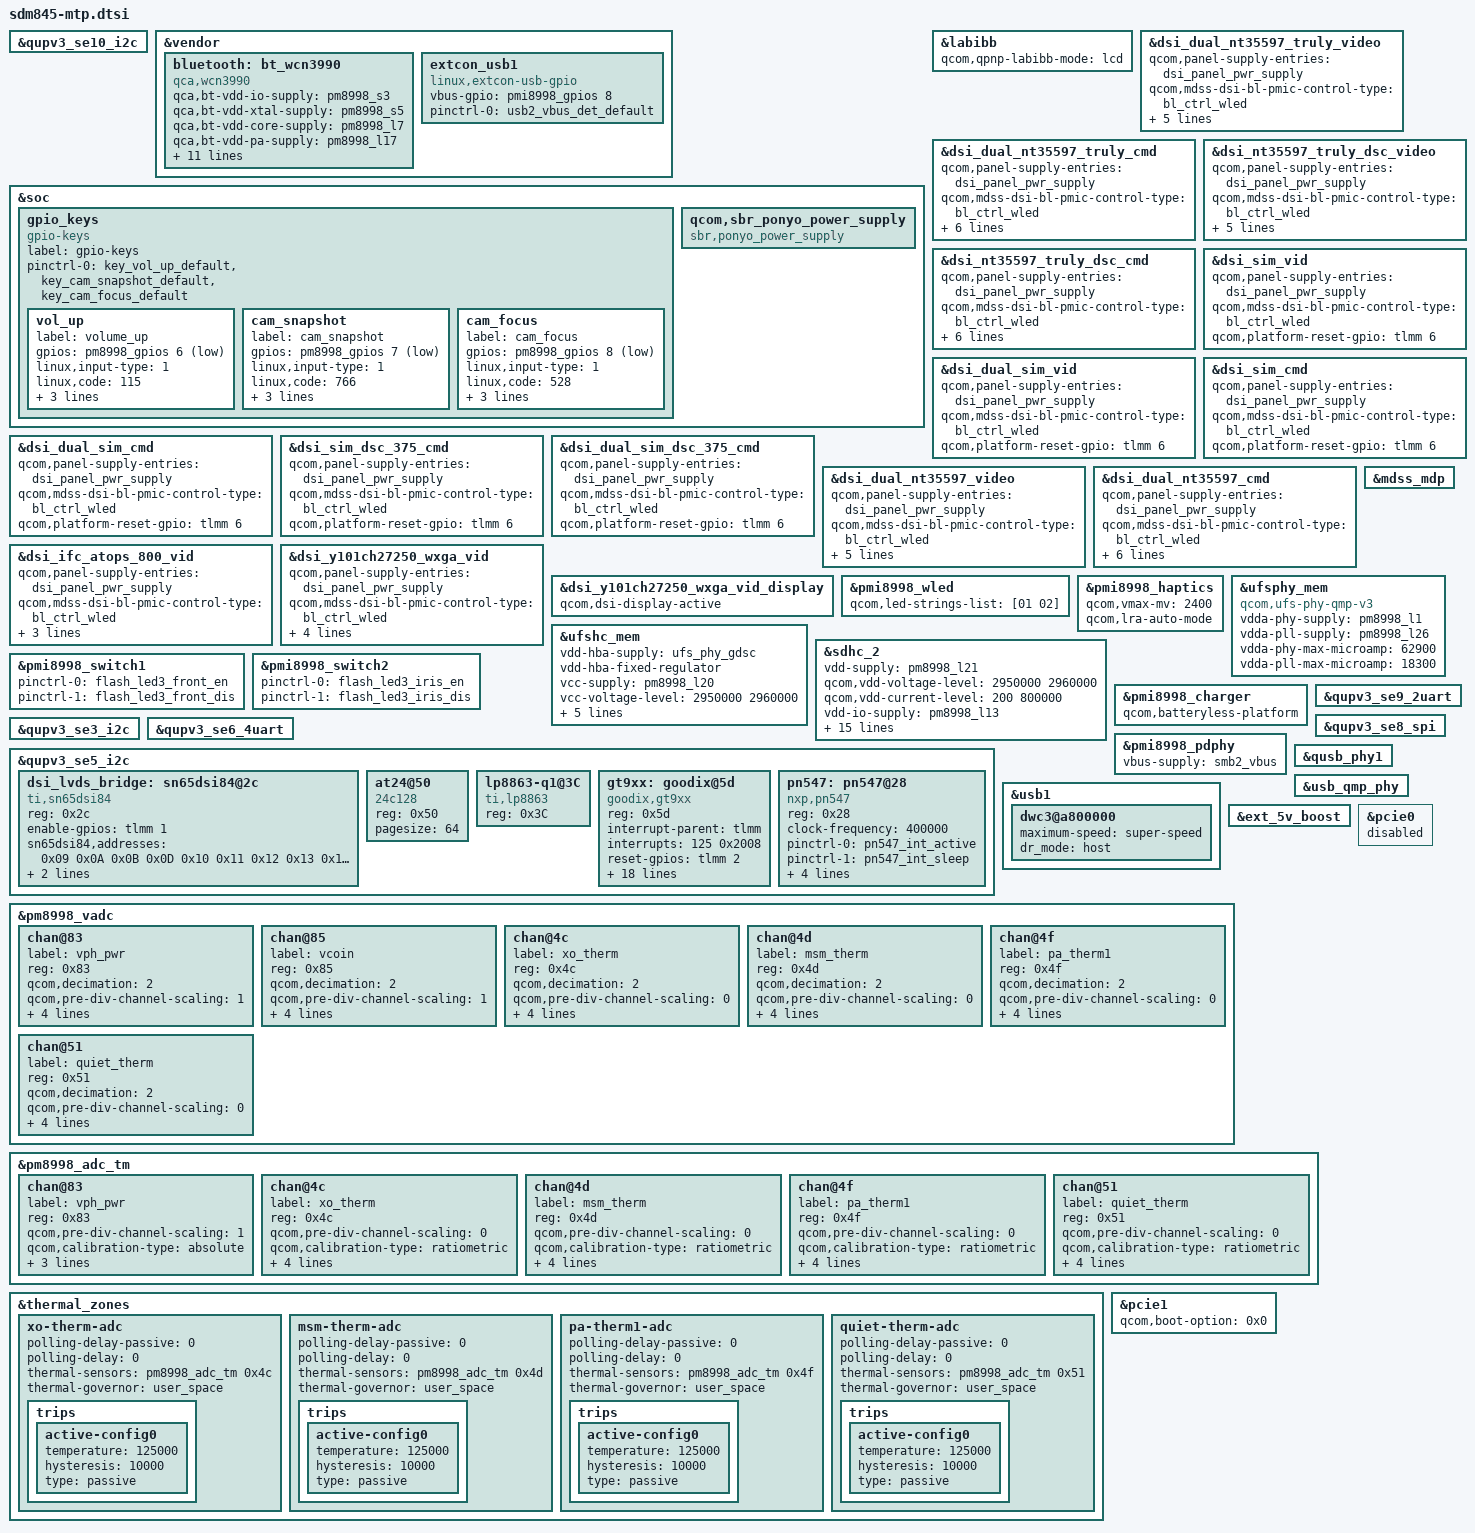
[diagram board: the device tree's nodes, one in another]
/* Copyright (c) 2016-2018, The Linux Foundation. All rights reserved.
 *
 * This program is free software; you can redistribute it and/or modify
 * it under the terms of the GNU General Public License version 2 and
 * only version 2 as published by the Free Software Foundation.
 *
 * This program is distributed in the hope that it will be useful,
 * but WITHOUT ANY WARRANTY; without even the implied warranty of
 * MERCHANTABILITY or FITNESS FOR A PARTICULAR PURPOSE.  See the
 * GNU General Public License for more details.
 */

#include <dt-bindings/gpio/gpio.h>
#include "sdm845-pmic-overlay.dtsi"
#include "sdm845-pinctrl-overlay.dtsi"
#include "sdm845-camera-sensor-mtp.dtsi"

&qupv3_se10_i2c {
#include "smb1355.dtsi"
};

&vendor {
	bluetooth: bt_wcn3990 {
		compatible = "qca,wcn3990";
		qca,bt-vdd-io-supply = <&pm8998_s3>;
		qca,bt-vdd-xtal-supply = <&pm8998_s5>;
		qca,bt-vdd-core-supply = <&pm8998_l7>;
		qca,bt-vdd-pa-supply = <&pm8998_l17>;
		qca,bt-vdd-ldo-supply = <&pm8998_l25>;

		qca,bt-vdd-io-voltage-level = <1352000 1352000>;
		qca,bt-vdd-xtal-voltage-level = <2040000 2040000>;
		qca,bt-vdd-core-voltage-level = <1800000 1800000>;
		qca,bt-vdd-pa-voltage-level = <1304000 1304000>;
		qca,bt-vdd-ldo-voltage-level = <3312000 3312000>;

		qca,bt-vdd-io-current-level = <1>; /* LPM/PFM */
		qca,bt-vdd-xtal-current-level = <1>; /* LPM/PFM */
		qca,bt-vdd-core-current-level = <1>; /* LPM/PFM */
		qca,bt-vdd-pa-current-level = <1>; /* LPM/PFM */
		qca,bt-vdd-ldo-current-level = <1>; /* LPM/PFM */
	};
};

&soc {
	gpio_keys {
		compatible = "gpio-keys";
		label = "gpio-keys";

		pinctrl-names = "default";
		pinctrl-0 = <&key_vol_up_default
			     &key_cam_snapshot_default
			     &key_cam_focus_default>;

		vol_up {
			label = "volume_up";
			gpios = <&pm8998_gpios 6 GPIO_ACTIVE_LOW>;
			linux,input-type = <1>;
			linux,code = <115>;
			gpio-key,wakeup;
			debounce-interval = <15>;
			linux,can-disable;
		};

		cam_snapshot {
			label = "cam_snapshot";
			gpios = <&pm8998_gpios 7 GPIO_ACTIVE_LOW>;
			linux,input-type = <1>;
			linux,code = <766>;
			gpio-key,wakeup;
			debounce-interval = <15>;
			linux,can-disable;
		};

		cam_focus {
			label = "cam_focus";
			gpios = <&pm8998_gpios 8 GPIO_ACTIVE_LOW>;
			linux,input-type = <1>;
			linux,code = <528>;
			gpio-key,wakeup;
			debounce-interval = <15>;
			linux,can-disable;
		};
	};

	qcom,sbr_ponyo_power_supply {
		compatible = "sbr,ponyo_power_supply";
		status = "okay";
	};

};

&labibb {
	status = "ok";
	qcom,qpnp-labibb-mode = "lcd";
};

&dsi_dual_nt35597_truly_video {
	qcom,panel-supply-entries = <&dsi_panel_pwr_supply>;
	qcom,mdss-dsi-bl-pmic-control-type = "bl_ctrl_wled";
	qcom,mdss-dsi-bl-min-level = <1>;
	qcom,mdss-dsi-bl-max-level = <4095>;
	qcom,mdss-dsi-mode-sel-gpio-state = "dual_port";
	qcom,panel-mode-gpio = <&tlmm 52 0>;
	qcom,platform-reset-gpio = <&tlmm 6 0>;
};

&dsi_dual_nt35597_truly_cmd {
	qcom,panel-supply-entries = <&dsi_panel_pwr_supply>;
	qcom,mdss-dsi-bl-pmic-control-type = "bl_ctrl_wled";
	qcom,mdss-dsi-bl-min-level = <1>;
	qcom,mdss-dsi-bl-max-level = <4095>;
	qcom,mdss-dsi-mode-sel-gpio-state = "dual_port";
	qcom,panel-mode-gpio = <&tlmm 52 0>;
	qcom,platform-reset-gpio = <&tlmm 6 0>;
	qcom,platform-te-gpio = <&tlmm 10 0>;
};

&dsi_nt35597_truly_dsc_video {
	qcom,panel-supply-entries = <&dsi_panel_pwr_supply>;
	qcom,mdss-dsi-bl-pmic-control-type = "bl_ctrl_wled";
	qcom,mdss-dsi-bl-min-level = <1>;
	qcom,mdss-dsi-bl-max-level = <4095>;
	qcom,mdss-dsi-mode-sel-gpio-state = "single_port";
	qcom,panel-mode-gpio = <&tlmm 52 0>;
	qcom,platform-reset-gpio = <&tlmm 6 0>;
};

&dsi_nt35597_truly_dsc_cmd {
	qcom,panel-supply-entries = <&dsi_panel_pwr_supply>;
	qcom,mdss-dsi-bl-pmic-control-type = "bl_ctrl_wled";
	qcom,mdss-dsi-bl-min-level = <1>;
	qcom,mdss-dsi-bl-max-level = <4095>;
	qcom,mdss-dsi-mode-sel-gpio-state = "single_port";
	qcom,panel-mode-gpio = <&tlmm 52 0>;
	qcom,platform-reset-gpio = <&tlmm 6 0>;
	qcom,platform-te-gpio = <&tlmm 10 0>;
};

&dsi_sim_vid {
	qcom,panel-supply-entries = <&dsi_panel_pwr_supply>;
	qcom,mdss-dsi-bl-pmic-control-type = "bl_ctrl_wled";
	qcom,platform-reset-gpio = <&tlmm 6 0>;
};

&dsi_dual_sim_vid {
	qcom,panel-supply-entries = <&dsi_panel_pwr_supply>;
	qcom,mdss-dsi-bl-pmic-control-type = "bl_ctrl_wled";
	qcom,platform-reset-gpio = <&tlmm 6 0>;
};

&dsi_sim_cmd {
	qcom,panel-supply-entries = <&dsi_panel_pwr_supply>;
	qcom,mdss-dsi-bl-pmic-control-type = "bl_ctrl_wled";
	qcom,platform-reset-gpio = <&tlmm 6 0>;
};

&dsi_dual_sim_cmd {
	qcom,panel-supply-entries = <&dsi_panel_pwr_supply>;
	qcom,mdss-dsi-bl-pmic-control-type = "bl_ctrl_wled";
	qcom,platform-reset-gpio = <&tlmm 6 0>;
};

&dsi_sim_dsc_375_cmd {
	qcom,panel-supply-entries = <&dsi_panel_pwr_supply>;
	qcom,mdss-dsi-bl-pmic-control-type = "bl_ctrl_wled";
	qcom,platform-reset-gpio = <&tlmm 6 0>;
};

&dsi_dual_sim_dsc_375_cmd {
	qcom,panel-supply-entries = <&dsi_panel_pwr_supply>;
	qcom,mdss-dsi-bl-pmic-control-type = "bl_ctrl_wled";
	qcom,platform-reset-gpio = <&tlmm 6 0>;
};

&dsi_dual_nt35597_video {
	qcom,panel-supply-entries = <&dsi_panel_pwr_supply>;
	qcom,mdss-dsi-bl-pmic-control-type = "bl_ctrl_wled";
	qcom,mdss-dsi-bl-min-level = <1>;
	qcom,mdss-dsi-bl-max-level = <4095>;
	qcom,mdss-dsi-mode-sel-gpio-state = "dual_port";
	qcom,panel-mode-gpio = <&tlmm 52 0>;
	qcom,platform-reset-gpio = <&tlmm 6 0>;

};

&dsi_dual_nt35597_cmd {
	qcom,panel-supply-entries = <&dsi_panel_pwr_supply>;
	qcom,mdss-dsi-bl-pmic-control-type = "bl_ctrl_wled";
	qcom,mdss-dsi-bl-min-level = <1>;
	qcom,mdss-dsi-bl-max-level = <4095>;
	qcom,mdss-dsi-mode-sel-gpio-state = "dual_port";
	qcom,panel-mode-gpio = <&tlmm 52 0>;
	qcom,platform-reset-gpio = <&tlmm 6 0>;
	qcom,platform-te-gpio = <&tlmm 10 0>;
};

&dsi_ifc_atops_800_vid {
	qcom,panel-supply-entries = <&dsi_panel_pwr_supply>;
        qcom,mdss-dsi-bl-pmic-control-type = "bl_ctrl_wled";
        qcom,mdss-dsi-bl-min-level = <1>;
        qcom,mdss-dsi-bl-max-level = <4095>;
	qcom,platform-reset-gpio = <&tlmm 87 0>;
	//qcom,mdss-dsi-mode-sel-gpio-state = "single_port";
	//qcom,platform-bklight-en-gpio = <&tlmm 88 0>;
	//qcom,mdss-dsi-pwm-gpio = <&pmi8998_gpios 5 GPIO_ACTIVE_HIGH>;
};

&dsi_y101ch27250_wxga_vid {
	qcom,panel-supply-entries = <&dsi_panel_pwr_supply>;
	qcom,mdss-dsi-bl-pmic-control-type = "bl_ctrl_wled";
	qcom,mdss-dsi-bl-min-level = <1>;
	qcom,mdss-dsi-bl-max-level = <4095>;
	qcom,platform-reset-gpio = <&tlmm 87 0>;
	qcom,mdss-dsi-mode-sel-gpio-state = "single_port";
};

/*
&dsi_nt35597_truly_dsc_cmd_display {
	qcom,dsi-display-active;
}; */
/*
&dsi_ifc_atops_800_vid_display {
	qcom,dsi-display-active;
};
*/
&dsi_y101ch27250_wxga_vid_display {
	qcom,dsi-display-active;
};
/*
&dsi_sim_vid_display {
	qcom,dsi-display-active;
};*/

&pmi8998_wled {
	status = "okay";
	qcom,led-strings-list = [01 02];
};

&pmi8998_haptics {
	qcom,vmax-mv = <2400>;
	qcom,lra-auto-mode;
	status = "okay";
};

&mdss_mdp {
	#cooling-cells = <2>;
};

&ufsphy_mem {
	compatible = "qcom,ufs-phy-qmp-v3";

	vdda-phy-supply = <&pm8998_l1>; /* 0.88v */
	vdda-pll-supply = <&pm8998_l26>; /* 1.2v */
	vdda-phy-max-microamp = <62900>;
	vdda-pll-max-microamp = <18300>;

	status = "ok";
};

&ufshc_mem {
	vdd-hba-supply = <&ufs_phy_gdsc>;
	vdd-hba-fixed-regulator;
	vcc-supply = <&pm8998_l20>;
	vcc-voltage-level = <2950000 2960000>;
	vccq2-supply = <&pm8998_s4>;
	vcc-max-microamp = <600000>;
	vccq2-max-microamp = <600000>;

	qcom,vddp-ref-clk-supply = <&pm8998_l2>;
	qcom,vddp-ref-clk-max-microamp = <100>;

	status = "ok";
};

&sdhc_2 {
	vdd-supply = <&pm8998_l21>;
	qcom,vdd-voltage-level = <2950000 2960000>;
	qcom,vdd-current-level = <200 800000>;

	vdd-io-supply = <&pm8998_l13>;
	qcom,vdd-io-voltage-level = <1808000 2960000>;
	qcom,vdd-io-current-level = <200 22000>;

	pinctrl-names = "active", "sleep", "ds_400KHz",
			"ds_50MHz", "ds_100MHz", "ds_200MHz";
	pinctrl-0 = <&sdc2_clk_on  &sdc2_cmd_on &sdc2_data_on &storage_cd>;
	pinctrl-1 = <&sdc2_clk_off &sdc2_cmd_off &sdc2_data_off &storage_cd>;
	pinctrl-2 = <&sdc2_clk_ds_400KHz
			&sdc2_cmd_ds_400KHz &sdc2_data_ds_400KHz>;
	pinctrl-3 = <&sdc2_clk_ds_50MHz
			&sdc2_cmd_ds_50MHz &sdc2_data_ds_50MHz>;
	pinctrl-4 = <&sdc2_clk_ds_100MHz
			&sdc2_cmd_ds_100MHz &sdc2_data_ds_100MHz>;
	pinctrl-5 = <&sdc2_clk_ds_200MHz
			&sdc2_cmd_ds_200MHz &sdc2_data_ds_200MHz>;

	cd-gpios = <&tlmm 126 GPIO_ACTIVE_LOW>;

	status = "ok";
};

&pmi8998_switch1 {
	pinctrl-names = "led_enable", "led_disable";
	pinctrl-0 = <&flash_led3_front_en>;
	pinctrl-1 = <&flash_led3_front_dis>;
};

&pmi8998_switch2 {
	pinctrl-names = "led_enable", "led_disable";
	pinctrl-0 = <&flash_led3_iris_en>;
	pinctrl-1 = <&flash_led3_iris_dis>;
};

&pmi8998_charger {
        qcom,batteryless-platform;
};


&vendor {

	extcon_usb1: extcon_usb1 {
		compatible = "linux,extcon-usb-gpio";
		vbus-gpio = <&pmi8998_gpios 8 GPIO_ACTIVE_HIGH>;

		pinctrl-names = "default";
		pinctrl-0 = <&usb2_vbus_det_default>;
	};
};

&qupv3_se9_2uart {
	status = "ok";
};

&qupv3_se8_spi {
	status = "ok";
};

&qupv3_se3_i2c {
	status = "ok";
/*
	nq@28 {
		compatible = "qcom,nq-nci";
		reg = <0x28>;
		qcom,nq-irq = <&tlmm 63 0x00>;
		qcom,nq-ven = <&tlmm 12 0x00>;
		qcom,nq-firm = <&tlmm 62 0x00>;
		qcom,nq-clkreq = <&pm8998_gpios 21 0x00>;
		qcom,nq-esepwr = <&tlmm 116 0x00>;
		interrupt-parent = <&tlmm>;
		interrupts = <63 0>;
		interrupt-names = "nfc_irq";
		pinctrl-names = "nfc_active", "nfc_suspend";
		pinctrl-0 = <&nfc_int_active
			     &nfc_enable_active
			     &nfc_clk_default>;
		pinctrl-1 = <&nfc_int_suspend &nfc_enable_suspend>;
	};
*/
};

&qupv3_se10_i2c {
	status = "ok";
};

&qupv3_se6_4uart {
	status = "ok";
};

&qupv3_se5_i2c {
	status = "ok";

	dsi_lvds_bridge: sn65dsi84@2c {
		compatible = "ti,sn65dsi84";
		reg = <0x2c>;
		status = "okay";

		enable-gpios = <&tlmm 1 0x00>;

		sn65dsi84,addresses = < 0x09 0x0A 0x0B 0x0D 0x10 0x11 0x12 0x13
			                0x18 0x19 0x1A 0x1B 0x20 0x21 0x22 0x23
			                0x24 0x25 0x26 0x27 0x28 0x29 0x2A 0x2B
			                0x2C 0x2D 0x2E 0x2F 0x30 0x31 0x32 0x33
			                0x34 0x35 0x36 0x37 0x38 0x39 0x3A 0x3B
			                0x3C 0x3D 0x3E 0x0D>;

		sn65dsi84,values =    < 0x00 0x05 0x10 0x00 0x26 0x00 0x2B 0x00
			                0x58 0x05 0x03 0x00 0x20 0x03 0x00 0x00
			                0x00 0x00 0x00 0x00 0x21 0x00 0x00 0x00
			                0x18 0x00 0x00 0x00 0x03 0x00 0x00 0x00
			                0x38 0x00 0x14 0x00 0x50 0x00 0x00 0x00
			                0x00 0x00 0x00 0x01>;
	};

	at24@50 {
		compatible = "24c128";
		reg = <0x50>;
		pagesize = <64>;
		status = "ok";
	};

	lp8863-q1@3C {
		status = "okay";
		compatible = "ti,lp8863";
		reg = <0x3C>;
	};

	gt9xx: goodix@5d {
		status = "okay";
		compatible = "goodix,gt9xx";
		reg = <0x5d>;
		interrupt-parent = <&tlmm>;
		interrupts = <125 0x2008>;
		reset-gpios = <&tlmm 2 0x00>;
		irq-gpios = <&tlmm 125 0x2008>;
		pinctrl-names = "gdix_ts_int_default", "gdix_ts_int_output_low",
			"gdix_ts_int_output_high", "gdix_ts_int_input",
			"gdix_ts_rst_default", "gdix_ts_rst_output_low",
			"gdix_ts_rst_output_high", "gdix_ts_rst_input";
		pinctrl-0 = <&ts_int_active>;
		pinctrl-1 = <&ts_int_suspend>;
		pinctrl-2 = <&ts_int_active>;
		pinctrl-3 = <&ts_int_active>;
		pinctrl-4 = <&ts_reset_active>;
		pinctrl-5 = <&ts_reset_suspend>;
		pinctrl-6 = <&ts_reset_active>;
		pinctrl-7 = <&ts_reset_active>;
		goodix,swap-x2y = <1>;
		touchscreen-size-x= <1280>;
		touchscreen-size-y= <800>;
		touchscreen-max-w = <255>;
		touchscreen-max-p = <255>;
		touchscreen-max-id= <255>;
		touchscreen-key-map= <158>, <102>, <139>;
		goodix,cfg-group0 = [
		00 20 03 00 05 0A 0C 00 01 0F
		14 0F 5A 46 03 05 00 00 00 00
		00 00 00 0D 0F 12 0A 8F 2F AA
		38 3B D3 07 00 00 00 9A 03 25
		00 00 00 00 00 00 00 00 00 00
		00 23 50 94 C5 02 07 00 00 04
		A9 26 00 95 2D 00 85 35 00 77
		3E 00 6C 49 00 6C 00 00 00 00
		00 00 00 00 00 00 00 00 00 00
		00 00 00 00 00 00 00 00 00 00
		00 00 00 00 00 00 00 00 00 00
		00 00 00 01 04 05 06 07 08 09
		0C 0D 0E 0F 10 11 14 15 16 17
		18 19 00 00 00 00 00 00 00 00
		00 00 00 02 04 06 07 08 0A 0C
		0D 0F 10 11 12 13 14 19 1B 1C
		1E 1F 20 21 22 23 24 25 26 27
		28 29 FF FF 00 00 00 00 00 00
		00 00 00 00 99 01];

	};

	pn547: pn547@28 {
	       status = "okay";
	       compatible = "nxp,pn547";
	       reg = <0x28>;
	       clock-frequency = <400000>;
	       pinctrl-names = "pn547_int_active", "pn547_int_sleep", "pn547_reset_active", "pn547_reset_sleep";
	       pinctrl-0 = <&pn547_int_active>;
	       pinctrl-1 = <&pn547_int_sleep>;
	       pinctrl-2 = <&pn547_reset_active>;
	       pinctrl-3 = <&pn547_reset_sleep>;
	       interrupt-gpios = <&tlmm 83 0x2008>;
	       enable-gpios = <&tlmm 84 0x00>;
       };
};

/*
&usb1 {
	extcon = <&extcon_usb1>;
};
*/

&pmi8998_pdphy {
	vbus-supply = <&smb2_vbus>;
};

&usb1 {
	status = "ok";
	dwc3@a800000 {
		maximum-speed = "super-speed";
		dr_mode = "host";
	};
};

&qusb_phy1 {
	status = "ok";
};

&usb_qmp_phy {
	status = "ok";
};


&ext_5v_boost {
	status = "ok";
};

&pm8998_vadc {
	chan@83 {
		label = "vph_pwr";
		reg = <0x83>;
		qcom,decimation = <2>;
		qcom,pre-div-channel-scaling = <1>;
		qcom,calibration-type = "absolute";
		qcom,scale-function = <0>;
		qcom,hw-settle-time = <0>;
		qcom,fast-avg-setup = <0>;
	};

	chan@85 {
		label = "vcoin";
		reg = <0x85>;
		qcom,decimation = <2>;
		qcom,pre-div-channel-scaling = <1>;
		qcom,calibration-type = "absolute";
		qcom,scale-function = <0>;
		qcom,hw-settle-time = <0>;
		qcom,fast-avg-setup = <0>;
	};

	chan@4c {
		label = "xo_therm";
		reg = <0x4c>;
		qcom,decimation = <2>;
		qcom,pre-div-channel-scaling = <0>;
		qcom,calibration-type = "ratiometric";
		qcom,scale-function = <4>;
		qcom,hw-settle-time = <2>;
		qcom,fast-avg-setup = <0>;
	};

	chan@4d {
		label = "msm_therm";
		reg = <0x4d>;
		qcom,decimation = <2>;
		qcom,pre-div-channel-scaling = <0>;
		qcom,calibration-type = "ratiometric";
		qcom,scale-function = <2>;
		qcom,hw-settle-time = <2>;
		qcom,fast-avg-setup = <0>;
	};

	chan@4f {
		label = "pa_therm1";
		reg = <0x4f>;
		qcom,decimation = <2>;
		qcom,pre-div-channel-scaling = <0>;
		qcom,calibration-type = "ratiometric";
		qcom,scale-function = <2>;
		qcom,hw-settle-time = <2>;
		qcom,fast-avg-setup = <0>;
	};

	chan@51 {
		label = "quiet_therm";
		reg = <0x51>;
		qcom,decimation = <2>;
		qcom,pre-div-channel-scaling = <0>;
		qcom,calibration-type = "ratiometric";
		qcom,scale-function = <2>;
		qcom,hw-settle-time = <2>;
		qcom,fast-avg-setup = <0>;
	};
};

&pm8998_adc_tm {
	chan@83 {
		label = "vph_pwr";
		reg = <0x83>;
		qcom,pre-div-channel-scaling = <1>;
		qcom,calibration-type = "absolute";
		qcom,scale-function = <0>;
		qcom,hw-settle-time = <0>;
		qcom,btm-channel-number = <0x60>;
	};

	chan@4c {
		label = "xo_therm";
		reg = <0x4c>;
		qcom,pre-div-channel-scaling = <0>;
		qcom,calibration-type = "ratiometric";
		qcom,scale-function = <4>;
		qcom,hw-settle-time = <2>;
		qcom,btm-channel-number = <0x68>;
		qcom,thermal-node;
	};

	chan@4d {
		label = "msm_therm";
		reg = <0x4d>;
		qcom,pre-div-channel-scaling = <0>;
		qcom,calibration-type = "ratiometric";
		qcom,scale-function = <2>;
		qcom,hw-settle-time = <2>;
		qcom,btm-channel-number = <0x70>;
		qcom,thermal-node;
	};

	chan@4f {
		label = "pa_therm1";
		reg = <0x4f>;
		qcom,pre-div-channel-scaling = <0>;
		qcom,calibration-type = "ratiometric";
		qcom,scale-function = <2>;
		qcom,hw-settle-time = <2>;
		qcom,btm-channel-number = <0x78>;
		qcom,thermal-node;
	};

	chan@51 {
		label = "quiet_therm";
		reg = <0x51>;
		qcom,pre-div-channel-scaling = <0>;
		qcom,calibration-type = "ratiometric";
		qcom,scale-function = <2>;
		qcom,hw-settle-time = <2>;
		qcom,btm-channel-number = <0x80>;
		qcom,thermal-node;
	};
};

&thermal_zones {
	xo-therm-adc {
		polling-delay-passive = <0>;
		polling-delay = <0>;
		thermal-sensors = <&pm8998_adc_tm 0x4c>;
		thermal-governor = "user_space";

		trips {
			active-config0 {
				temperature = <125000>;
				hysteresis = <10000>;
				type = "passive";
			};
		};
	};

	msm-therm-adc {
		polling-delay-passive = <0>;
		polling-delay = <0>;
		thermal-sensors = <&pm8998_adc_tm 0x4d>;
		thermal-governor = "user_space";

		trips {
			active-config0 {
				temperature = <125000>;
				hysteresis = <10000>;
				type = "passive";
			};
		};
	};

	pa-therm1-adc {
		polling-delay-passive = <0>;
		polling-delay = <0>;
		thermal-sensors = <&pm8998_adc_tm 0x4f>;
		thermal-governor = "user_space";

		trips {
			active-config0 {
				temperature = <125000>;
				hysteresis = <10000>;
				type = "passive";
			};
		};
	};

	quiet-therm-adc {
		polling-delay-passive = <0>;
		polling-delay = <0>;
		thermal-sensors = <&pm8998_adc_tm 0x51>;
		thermal-governor = "user_space";

		trips {
			active-config0 {
				temperature = <125000>;
				hysteresis = <10000>;
				type = "passive";
			};
		};
	};
};

&pcie0 {
	status = "disabled";
};

&pcie1 {
	status = "ok";
	qcom,boot-option = <0x0>;
};
